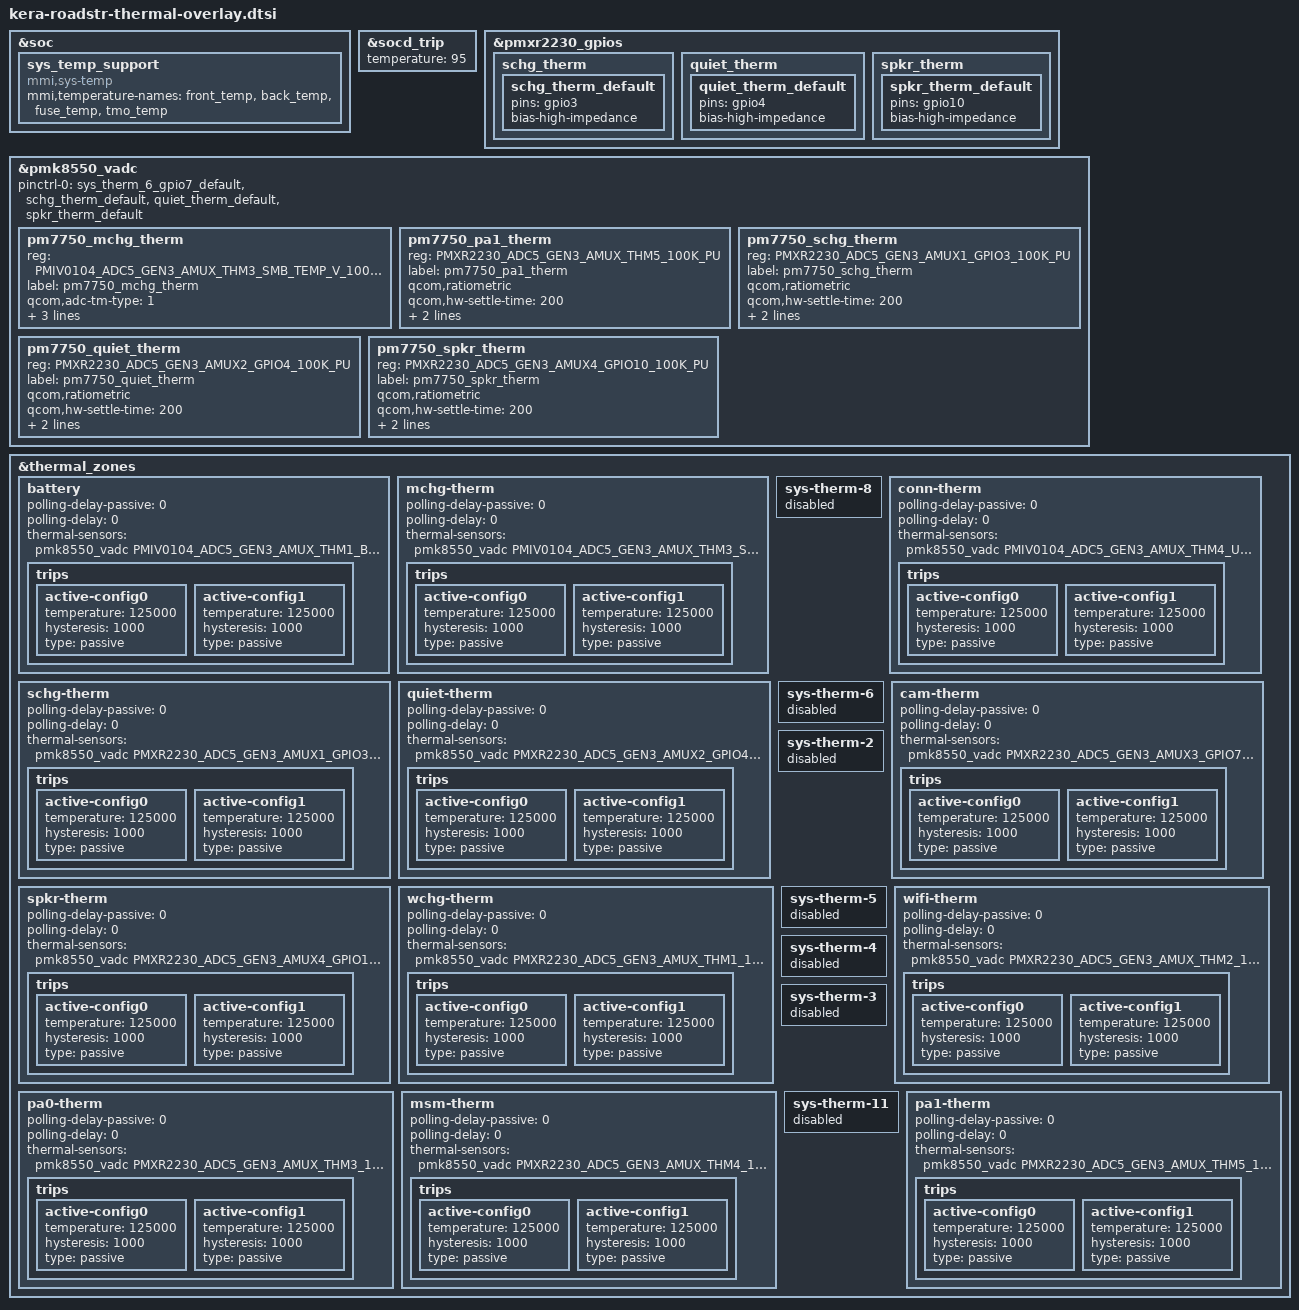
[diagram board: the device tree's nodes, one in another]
/* roadstr thermal dts*/
#include <dt-bindings/iio/qcom,spmi-adc5-gen3-pmxr2230.h>

&soc {
        sys_temp_support {
                compatible = "mmi,sys-temp";
                mmi,temperature-names = "front_temp",
                        "back_temp",
                        "fuse_temp",
                        "tmo_temp";
                status = "ok";
        };
};

&socd_trip {
    temperature = <95>;
};

&pmxr2230_gpios {
	schg_therm {
		schg_therm_default: schg_therm_default {
			pins = "gpio3";
			bias-high-impedance;
		};
	};

	quiet_therm {
		quiet_therm_default: quiet_therm_default {
			pins = "gpio4";
			bias-high-impedance;
		};
	};

	spkr_therm {
		spkr_therm_default: spkr_therm_default {
			pins = "gpio10";
			bias-high-impedance;
		};
	};
};

&pmk8550_vadc {
	pinctrl-names = "default";
	pinctrl-0 = <&sys_therm_6_gpio7_default &schg_therm_default &quiet_therm_default &spkr_therm_default>;

	pm7750_mchg_therm {
		reg = <PMIV0104_ADC5_GEN3_AMUX_THM3_SMB_TEMP_V_100K_PU>;
		label = "pm7750_mchg_therm";
		qcom,adc-tm-type = <1>;
		qcom,ratiometric;
		qcom,hw-settle-time = <200>;
		qcom,pre-scaling = <1 1>;
	};

	pm7750_pa1_therm {
                reg = <PMXR2230_ADC5_GEN3_AMUX_THM5_100K_PU>;
                label = "pm7750_pa1_therm";
                qcom,ratiometric;
                qcom,hw-settle-time = <200>;
                qcom,pre-scaling = <1 1>;
                qcom,adc-tm-type = <1>;
        };

	pm7750_schg_therm {
		reg = <PMXR2230_ADC5_GEN3_AMUX1_GPIO3_100K_PU>;
		label = "pm7750_schg_therm";
		qcom,ratiometric;
		qcom,hw-settle-time = <200>;
		qcom,pre-scaling = <1 1>;
		qcom,adc-tm-type = <1>;
	};

	pm7750_quiet_therm {
		reg = <PMXR2230_ADC5_GEN3_AMUX2_GPIO4_100K_PU>;
		label = "pm7750_quiet_therm";
		qcom,ratiometric;
		qcom,hw-settle-time = <200>;
		qcom,pre-scaling = <1 1>;
		qcom,adc-tm-type = <1>;
	};

	pm7750_spkr_therm {
		reg = <PMXR2230_ADC5_GEN3_AMUX4_GPIO10_100K_PU>;
		label = "pm7750_spkr_therm";
		qcom,ratiometric;
		qcom,hw-settle-time = <200>;
		qcom,pre-scaling = <1 1>;
		qcom,adc-tm-type = <1>;
	};
};

&thermal_zones {
	/* battery */
	battery {
		polling-delay-passive = <0>;
		polling-delay = <0>;
		thermal-sensors = <&pmk8550_vadc PMIV0104_ADC5_GEN3_AMUX_THM1_BATT_THERM_100K_PU>;
		trips {
			active-config0 {
				temperature = <125000>;
				hysteresis = <1000>;
				type = "passive";
			};

			active-config1 {
				temperature = <125000>;
				hysteresis = <1000>;
				type = "passive";
			};
		};
	};

	/* mchg-therm */
	mchg-therm {
		polling-delay-passive = <0>;
		polling-delay = <0>;
		thermal-sensors = <&pmk8550_vadc PMIV0104_ADC5_GEN3_AMUX_THM3_SMB_TEMP_V_100K_PU>;
		trips {
			active-config0 {
				temperature = <125000>;
				hysteresis = <1000>;
				type = "passive";
			};

			active-config1 {
				temperature = <125000>;
				hysteresis = <1000>;
				type = "passive";
			};
		};
	};

	/* usb-therm */
	sys-therm-8 {
		status = "disabled";
	};

	conn-therm {
                polling-delay-passive = <0>;
                polling-delay = <0>;
                thermal-sensors = <&pmk8550_vadc PMIV0104_ADC5_GEN3_AMUX_THM4_USB_THERM_100K_PU>;
                trips {
                        active-config0 {
                                temperature = <125000>;
                                hysteresis = <1000>;
                                type = "passive";
                        };

                        active-config1 {
                                temperature = <125000>;
                                hysteresis = <1000>;
                                type = "passive";
                        };
                };
        };

	/* schg-therm, gpio3 */
	schg-therm {
		polling-delay-passive = <0>;
		polling-delay = <0>;
		thermal-sensors = <&pmk8550_vadc PMXR2230_ADC5_GEN3_AMUX1_GPIO3_100K_PU>;
		trips {
			active-config0 {
				temperature = <125000>;
				hysteresis = <1000>;
				type = "passive";
			};

			active-config1 {
				temperature = <125000>;
				hysteresis = <1000>;
				type = "passive";
			};
		};
	};

	/* quiet-therm gpio4 */
	quiet-therm {
		polling-delay-passive = <0>;
		polling-delay = <0>;
		thermal-sensors = <&pmk8550_vadc PMXR2230_ADC5_GEN3_AMUX2_GPIO4_100K_PU>;
		trips {
			active-config0 {
				temperature = <125000>;
				hysteresis = <1000>;
				type = "passive";
			};

			active-config1 {
				temperature = <125000>;
				hysteresis = <1000>;
				type = "passive";
			};
		};
	};

	/* cam-therm gpio7 */
	sys-therm-6 {
		status = "disabled";
	};

	cam-therm {
		polling-delay-passive = <0>;
		polling-delay = <0>;
		thermal-sensors = <&pmk8550_vadc PMXR2230_ADC5_GEN3_AMUX3_GPIO7_100K_PU>;
		trips {
			active-config0 {
				temperature = <125000>;
				hysteresis = <1000>;
				type = "passive";
			};

			active-config1 {
				temperature = <125000>;
				hysteresis = <1000>;
				type = "passive";
			};
		};
	};

	/* spkr-therm gpio10 */
	spkr-therm {
		polling-delay-passive = <0>;
		polling-delay = <0>;
		thermal-sensors = <&pmk8550_vadc PMXR2230_ADC5_GEN3_AMUX4_GPIO10_100K_PU>;
		trips {
			active-config0 {
				temperature = <125000>;
				hysteresis = <1000>;
				type = "passive";
			};

			active-config1 {
				temperature = <125000>;
				hysteresis = <1000>;
				type = "passive";
			};
		};
	};

	/* wchg-therm */
	sys-therm-2 {
		status = "disabled";
	};

	wchg-therm {
		polling-delay-passive = <0>;
		polling-delay = <0>;
		thermal-sensors = <&pmk8550_vadc PMXR2230_ADC5_GEN3_AMUX_THM1_100K_PU>;
		trips {
			active-config0 {
				temperature = <125000>;
				hysteresis = <1000>;
				type = "passive";
			};

			active-config1 {
				temperature = <125000>;
				hysteresis = <1000>;
				type = "passive";
			};
		};
	};

	/* wifi-therm */
	sys-therm-5 {
		status = "disabled";
	};

	wifi-therm {
		polling-delay-passive = <0>;
		polling-delay = <0>;
		thermal-sensors = <&pmk8550_vadc PMXR2230_ADC5_GEN3_AMUX_THM2_100K_PU>;
		trips {
			active-config0 {
				temperature = <125000>;
				hysteresis = <1000>;
				type = "passive";
			};

			active-config1 {
				temperature = <125000>;
				hysteresis = <1000>;
				type = "passive";
			};
		};
	};

	/* pa0-therm */
	sys-therm-4 {
		status = "disabled";
	};

	pa0-therm {
		polling-delay-passive = <0>;
		polling-delay = <0>;
		thermal-sensors = <&pmk8550_vadc PMXR2230_ADC5_GEN3_AMUX_THM3_100K_PU>;
		trips {
			active-config0 {
				temperature = <125000>;
				hysteresis = <1000>;
				type = "passive";
			};

			active-config1 {
				temperature = <125000>;
				hysteresis = <1000>;
				type = "passive";
			};
		};
	};

	/* msm-therm */
	sys-therm-3 {
		status = "disabled";
	};

	msm-therm {
		polling-delay-passive = <0>;
		polling-delay = <0>;
		thermal-sensors = <&pmk8550_vadc PMXR2230_ADC5_GEN3_AMUX_THM4_100K_PU>;
		trips {
			active-config0 {
				temperature = <125000>;
				hysteresis = <1000>;
				type = "passive";
			};

			active-config1 {
				temperature = <125000>;
				hysteresis = <1000>;
				type = "passive";
			};
		};
	};

	/* pa1-therm */
	sys-therm-11 {
		status = "disabled";
	};

	pa1-therm {
		polling-delay-passive = <0>;
		polling-delay = <0>;
		thermal-sensors = <&pmk8550_vadc PMXR2230_ADC5_GEN3_AMUX_THM5_100K_PU>;
		trips {
			active-config0 {
				temperature = <125000>;
				hysteresis = <1000>;
				type = "passive";
			};

			active-config1 {
				temperature = <125000>;
				hysteresis = <1000>;
				type = "passive";
			};
		};
	};
};
